VERSION ""

NS_ :

BS_:

BU_: PUMA LabVIEW

BO_ 3221225472 VECTOR__INDEPENDENT_SIG_MSG: 0 Vector__XXX
 SG_ Fan_DC : 32|32@1- (1,0) [0|0] "" Vector__XXX

BO_ 1 Front_Axle_Force_Signals: 8 PUMA
 SG_ F_ACT_D1 : 0|32@1- (1,0) [0|0] "" Vector__XXX
 SG_ F_ACT_V1 : 32|32@1- (1,0) [0|0] "" Vector__XXX

BO_ 2 Rear_Axle_Force_Signals: 8 PUMA
 SG_ F_ACT_D2 : 0|32@1- (1,0) [0|0] "" Vector__XXX
 SG_ F_ACT_V2 : 32|32@1- (1,0) [0|0] "" Vector__XXX

BO_ 3 Total_SPD_and_Force: 8 PUMA
 SG_ F_ACT_D : 0|32@1- (1,0) [0|0] "" Vector__XXX
 SG_ F_ACT_V : 32|32@1- (1,0) [0|0] "" Vector__XXX

BO_ 4 Front_Axle_PWR_and_SPD_Signals: 8 PUMA
 SG_ P_ACT_D1 : 0|32@1- (1,0) [0|0] "" Vector__XXX
 SG_ V_ACT_D1 : 32|32@1- (1,0) [0|0] "" Vector__XXX

BO_ 5 Rear_Axle_PWR_and_SPD_Signals: 8 PUMA
 SG_ P_ACT_D2 : 0|32@1- (1,0) [0|0] "" Vector__XXX
 SG_ V_ACT_D2 : 32|32@1- (1,0) [0|0] "" Vector__XXX

BO_ 6 Total_PWR_and_ACC: 8 PUMA
 SG_ ACCEL_D : 0|32@1- (1,0) [0|0] "" Vector__XXX
 SG_ P_ACT_D : 32|32@1- (1,0) [0|0] "" Vector__XXX

BO_ 7 Time_and_Misc: 8 PUMA
 SG_ Time : 0|32@1+ (1,0) [0|0] "" Vector__XXX
 SG_ V_ACT_D : 32|32@1- (1,0) [0|0] "" Vector__XXX

BO_ 8 Set_Values: 8 PUMA
 SG_ V_SET : 32|32@1- (1,0) [0|0] "" Vector__XXX
 SG_ F_SET : 0|32@1- (1,0) [0|0] "" Vector__XXX

BO_ 9 Speed_and_Force: 8 PUMA
 SG_ Speed_kph : 0|32@1- (1,0) [0|0] "kph" Vector__XXX
 SG_ Force_N : 32|32@1- (1,0) [0|0] "N" Vector__XXX

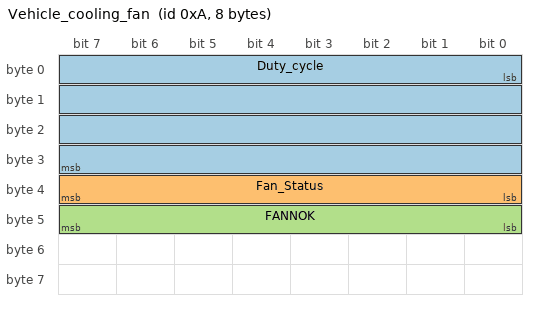
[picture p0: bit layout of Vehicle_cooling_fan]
BO_ 10 Vehicle_cooling_fan: 8 PUMA
 SG_ Duty_cycle : 0|32@1- (1,0) [0|0] "%" Vector__XXX
 SG_ Fan_Status : 32|8@1+ (1,0) [0|0] "" Vector__XXX
 SG_ FANNOK : 40|8@1+ (1,0) [0|0] "" Vector__XXX

BO_ 11 V_ACT: 8 PUMA
 SG_ V_ACT_kph : 0|32@1- (1,0) [0|0] "kph" Vector__XXX

CM_ BO_ 9 "Actual speed signal is seen on V_AVT and not on V_ACT_D";
CM_ SG_ 10 Fan_Status "1=On, 0=Off
";
CM_ SG_ 10 FANNOK "Fan_not_ok (as mentioned in description of k-AVL)
";
SIG_VALTYPE_ 1 F_ACT_D1 : 1;
SIG_VALTYPE_ 1 F_ACT_V1 : 1;
SIG_VALTYPE_ 2 F_ACT_D2 : 1;
SIG_VALTYPE_ 2 F_ACT_V2 : 1;
SIG_VALTYPE_ 3 F_ACT_D : 1;
SIG_VALTYPE_ 3 F_ACT_V : 1;
SIG_VALTYPE_ 4 P_ACT_D1 : 1;
SIG_VALTYPE_ 4 V_ACT_D1 : 1;
SIG_VALTYPE_ 5 P_ACT_D2 : 1;
SIG_VALTYPE_ 5 V_ACT_D2 : 1;
SIG_VALTYPE_ 6 ACCEL_D : 1;
SIG_VALTYPE_ 6 P_ACT_D : 1;
SIG_VALTYPE_ 7 V_ACT_D : 1;
SIG_VALTYPE_ 8 V_SET : 1;
SIG_VALTYPE_ 8 F_SET : 1;
SIG_VALTYPE_ 9 Speed_kph : 1;
SIG_VALTYPE_ 9 Force_N : 1;
SIG_VALTYPE_ 10 Duty_cycle : 1;
SIG_VALTYPE_ 11 V_ACT_kph : 1;
